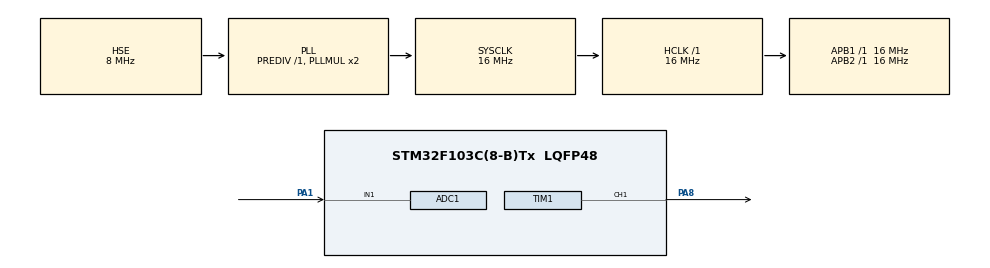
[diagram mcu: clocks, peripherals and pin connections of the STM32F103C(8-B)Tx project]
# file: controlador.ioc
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ADC1.Channel-0\#ChannelRegularConversion=ADC_CHANNEL_1
ADC1.NbrOfConversionFlag=1
ADC1.Rank-0\#ChannelRegularConversion=1
ADC1.SamplingTime-0\#ChannelRegularConversion=ADC_SAMPLETIME_1CYCLE_5
ADC1.master=1
Mcu.Family=STM32F1
Mcu.Name=STM32F103C(8-B)Tx
Mcu.Package=LQFP48
NVIC.PriorityGroup=NVIC_PRIORITYGROUP_4
NVIC.TIM2_IRQn=true\:0\:0\:false\:false\:true\:true\:true\:true
PA1.Signal=ADCx_IN1
PA13.Mode=Serial_Wire
PA13.Signal=SYS_JTMS-SWDIO
PA14.Mode=Serial_Wire
PA14.Signal=SYS_JTCK-SWCLK
PA8.Signal=S_TIM1_CH1
PD0-OSC_IN.Mode=HSE-External-Oscillator
PD0-OSC_IN.Signal=RCC_OSC_IN
PD1-OSC_OUT.Mode=HSE-External-Oscillator
PD1-OSC_OUT.Signal=RCC_OSC_OUT
ProjectManager.HeapSize=0x200
ProjectManager.StackSize=0x400
ProjectManager.TargetToolchain=STM32CubeIDE
RCC.AHBFreq_Value=16000000
RCC.APB1Freq_Value=16000000
RCC.APB1TimFreq_Value=16000000
RCC.APB2Freq_Value=16000000
RCC.APB2TimFreq_Value=16000000
RCC.HCLKFreq_Value=16000000
RCC.PLLSourceVirtual=RCC_PLLSOURCE_HSE
RCC.SYSCLKFreq_VALUE=16000000
RCC.SYSCLKSource=RCC_SYSCLKSOURCE_PLLCLK
RCC.USBFreq_Value=16000000
SH.ADCx_IN1.0=ADC1_IN1,IN1
SH.S_TIM1_CH1.0=TIM1_CH1,PWM Generation1 CH1
TIM1.Channel-PWM\ Generation1\ CH1=TIM_CHANNEL_1
TIM1.Period=3200-1
TIM2.Period=3200-1
TIM2.Prescaler=0
VP_TIM1_VS_ClockSourceINT.Mode=Internal
VP_TIM2_VS_ClockSourceINT.Mode=Internal
board=custom

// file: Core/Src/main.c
/* USER CODE BEGIN Header */
/**
  (1/16MHz) * 3200 = 200us -> 5000 Hz
  */
/* USER CODE END Header */
#include "main.h"

/* USER CODE BEGIN Includes */
#define TIMER_COUNTER (3200-1-500)
#define ARRAY_MAX_SIZE 2

// transdutor
#define ADC_SCALE_FACTOR (3.3f / 4096.0f)  //  3.3V em um ADC de 12bits
// #define TRANSDUCTOR_GAIN 0.1
#define TRANSDUCTOR_GAIN 0.085227273

// ref
#define PI 		3.14159265359f
#define F  		50     // Frequência da senoide (50 Hz)
#define Fs 		5000   // Frequência de amostragem (5 kHz)
#define Ts      (1.0f/Fs)
#define A  		6      // Amplitude
//#define OFFSET 	12
#define OFFSET 	10 // -2 por conta do teste empirco
#define WAVE_TABLE_SIZE (Fs/F)

// controlador
//opção 1
//#define Kp 0.062f
//#define Ki 0.17f
//#define Kd 0.05f
//opção 2
//#define Kp 0.07f
//#define Ki 0.18f
//#define Kd 0.05f
//opção 2
//#define Kp 0.07f
//#define Ki 0.2f
//#define Kd 0.05f
//opção 2
#define Kp 0.09f
#define Ki 0.2f
#define Kd 0.05f

// alimentação
// #define E 24.0f
#define E 30.0f

// duty_cycle
// 16MHz/5kHz = 3200
#define DUTY_CICLE_CONST (TIMER_COUNTER/E) // (SAMPLES_PER_PERIOD/E)

/* USER CODE END Includes */

ADC_HandleTypeDef hadc1;

TIM_HandleTypeDef htim1;
TIM_HandleTypeDef htim2;

void SystemClock_Config(void);
static void MX_GPIO_Init(void);
static void MX_ADC1_Init(void);
static void MX_TIM2_Init(void);
static void MX_TIM1_Init(void);

/* USER CODE BEGIN 0 */
int curr_idx = 0;

/*
 * Sinal de referencia sera uma senoidal com offset de 12V, amplitude de 6V e freq de 50 Hz
 *
 * Obs: ao invés de calcular a cada iteração eu poderia simplesmente armazernar todo um
 * periodo da senoidal já q o sinal de ref não se altera
 */
float ref_signal[WAVE_TABLE_SIZE] = {0};
uint8_t ref_idx = 0;

/*
 * Transdutor -> um dispositivo que transforma um tipo de energia em outro
 *
 * basicamente um sensor, o que em nosso caso seria o divisor de tensão que permite
 * lermos a tensão do sistema pelo ADC
 * */
float transductor_input[ARRAY_MAX_SIZE] = {0};
float prev_transductor_val = 0;
uint16_t adc_val = 0;

/*
 * Error é o array que contem o erro do sistema
 * basicamente é o valor da diferença entre o sinal de referencia e o sinal medido
 */
float error[ARRAY_MAX_SIZE] = {0};
float prev_error = 0;

/*
 * Controlador PID
 * uP(k) = Kp*e(k)
 * uI(k) = uI(k-1) + Ki*e(k)*Ts
 * uD(k) = Kd*((e(k) - e(k-1))/Ts)
 * uPID = uP(k) + uI(k) + uD(k)
 */
float cP = 0;
float cI[ARRAY_MAX_SIZE] = {0};
float cD = 0;
float prev_cI_output = 0;
float pid_output = 0;

/*
 * Duty cycle
 */
uint16_t duty_cycle = 0;

/* USER CODE END 0 */

int main(void)
{

  /* USER CODE BEGIN 1 */
  for (int i = 0; i < WAVE_TABLE_SIZE; i++) {
	ref_signal[i] = A * sinf(2 * PI * F * i * Ts) + OFFSET;
  }
  /* USER CODE END 1 */

  /* MCU Configuration--------------------------------------------------------*/

  /* Reset of all peripherals, Initializes the Flash interface and the Systick. */
  HAL_Init();

  /* Configure the system clock */
  SystemClock_Config();

  /* Initialize all configured peripherals */
  MX_GPIO_Init();
  MX_ADC1_Init();
  MX_TIM2_Init();
  MX_TIM1_Init();
  /* USER CODE BEGIN 2 */

  HAL_TIM_Base_Start_IT(&htim2);
  HAL_TIM_PWM_Start(&htim1, TIM_CHANNEL_1);
  __HAL_TIM_SET_COMPARE(&htim1, TIM_CHANNEL_1, TIMER_COUNTER/2);
  /* USER CODE END 2 */

  /* Infinite loop */
  while (1)
  {

  }
}

void SystemClock_Config(void)
{
  RCC_OscInitTypeDef RCC_OscInitStruct = {0};
  RCC_ClkInitTypeDef RCC_ClkInitStruct = {0};
  RCC_PeriphCLKInitTypeDef PeriphClkInit = {0};

  /** Initializes the RCC Oscillators according to the specified parameters
  * in the RCC_OscInitTypeDef structure.
  */
  RCC_OscInitStruct.OscillatorType = RCC_OSCILLATORTYPE_HSE;
  RCC_OscInitStruct.HSEState = RCC_HSE_ON;
  RCC_OscInitStruct.HSEPredivValue = RCC_HSE_PREDIV_DIV1;
  RCC_OscInitStruct.HSIState = RCC_HSI_ON;
  RCC_OscInitStruct.PLL.PLLState = RCC_PLL_ON;
  RCC_OscInitStruct.PLL.PLLSource = RCC_PLLSOURCE_HSE;
  RCC_OscInitStruct.PLL.PLLMUL = RCC_PLL_MUL2;
  if (HAL_RCC_OscConfig(&RCC_OscInitStruct) != HAL_OK)
  {
    Error_Handler();
  }

  /** Initializes the CPU, AHB and APB buses clocks
  */
  RCC_ClkInitStruct.ClockType = RCC_CLOCKTYPE_HCLK|RCC_CLOCKTYPE_SYSCLK
                              |RCC_CLOCKTYPE_PCLK1|RCC_CLOCKTYPE_PCLK2;
  RCC_ClkInitStruct.SYSCLKSource = RCC_SYSCLKSOURCE_PLLCLK;
  RCC_ClkInitStruct.AHBCLKDivider = RCC_SYSCLK_DIV1;
  RCC_ClkInitStruct.APB1CLKDivider = RCC_HCLK_DIV1;
  RCC_ClkInitStruct.APB2CLKDivider = RCC_HCLK_DIV1;

  if (HAL_RCC_ClockConfig(&RCC_ClkInitStruct, FLASH_LATENCY_0) != HAL_OK)
  {
    Error_Handler();
  }
  PeriphClkInit.PeriphClockSelection = RCC_PERIPHCLK_ADC;
  PeriphClkInit.AdcClockSelection = RCC_ADCPCLK2_DIV2;
  if (HAL_RCCEx_PeriphCLKConfig(&PeriphClkInit) != HAL_OK)
  {
    Error_Handler();
  }
}

static void MX_ADC1_Init(void)
{

  ADC_ChannelConfTypeDef sConfig = {0};

  /** Common config
  */
  hadc1.Instance = ADC1;
  hadc1.Init.ScanConvMode = ADC_SCAN_DISABLE;
  hadc1.Init.ContinuousConvMode = DISABLE;
  hadc1.Init.DiscontinuousConvMode = DISABLE;
  hadc1.Init.ExternalTrigConv = ADC_SOFTWARE_START;
  hadc1.Init.DataAlign = ADC_DATAALIGN_RIGHT;
  hadc1.Init.NbrOfConversion = 1;
  if (HAL_ADC_Init(&hadc1) != HAL_OK)
  {
    Error_Handler();
  }

  /** Configure Regular Channel
  */
  sConfig.Channel = ADC_CHANNEL_1;
  sConfig.Rank = ADC_REGULAR_RANK_1;
  sConfig.SamplingTime = ADC_SAMPLETIME_1CYCLE_5;
  if (HAL_ADC_ConfigChannel(&hadc1, &sConfig) != HAL_OK)
  {
    Error_Handler();
  }

}

static void MX_TIM1_Init(void)
{

  TIM_ClockConfigTypeDef sClockSourceConfig = {0};
  TIM_MasterConfigTypeDef sMasterConfig = {0};
  TIM_OC_InitTypeDef sConfigOC = {0};
  TIM_BreakDeadTimeConfigTypeDef sBreakDeadTimeConfig = {0};

  htim1.Instance = TIM1;
  htim1.Init.Prescaler = 0;
  htim1.Init.CounterMode = TIM_COUNTERMODE_UP;
  htim1.Init.Period = 3200-1;
  htim1.Init.ClockDivision = TIM_CLOCKDIVISION_DIV1;
  htim1.Init.RepetitionCounter = 0;
  htim1.Init.AutoReloadPreload = TIM_AUTORELOAD_PRELOAD_DISABLE;
  if (HAL_TIM_Base_Init(&htim1) != HAL_OK)
  {
    Error_Handler();
  }
  sClockSourceConfig.ClockSource = TIM_CLOCKSOURCE_INTERNAL;
  if (HAL_TIM_ConfigClockSource(&htim1, &sClockSourceConfig) != HAL_OK)
  {
    Error_Handler();
  }
  if (HAL_TIM_PWM_Init(&htim1) != HAL_OK)
  {
    Error_Handler();
  }
  sMasterConfig.MasterOutputTrigger = TIM_TRGO_RESET;
  sMasterConfig.MasterSlaveMode = TIM_MASTERSLAVEMODE_DISABLE;
  if (HAL_TIMEx_MasterConfigSynchronization(&htim1, &sMasterConfig) != HAL_OK)
  {
    Error_Handler();
  }
  sConfigOC.OCMode = TIM_OCMODE_PWM1;
  sConfigOC.Pulse = 0;
  sConfigOC.OCPolarity = TIM_OCPOLARITY_HIGH;
  sConfigOC.OCNPolarity = TIM_OCNPOLARITY_HIGH;
  sConfigOC.OCFastMode = TIM_OCFAST_DISABLE;
  sConfigOC.OCIdleState = TIM_OCIDLESTATE_RESET;
  sConfigOC.OCNIdleState = TIM_OCNIDLESTATE_RESET;
  if (HAL_TIM_PWM_ConfigChannel(&htim1, &sConfigOC, TIM_CHANNEL_1) != HAL_OK)
  {
    Error_Handler();
  }
  sBreakDeadTimeConfig.OffStateRunMode = TIM_OSSR_DISABLE;
  sBreakDeadTimeConfig.OffStateIDLEMode = TIM_OSSI_DISABLE;
  sBreakDeadTimeConfig.LockLevel = TIM_LOCKLEVEL_OFF;
  sBreakDeadTimeConfig.DeadTime = 0;
  sBreakDeadTimeConfig.BreakState = TIM_BREAK_DISABLE;
  sBreakDeadTimeConfig.BreakPolarity = TIM_BREAKPOLARITY_HIGH;
  sBreakDeadTimeConfig.AutomaticOutput = TIM_AUTOMATICOUTPUT_DISABLE;
  if (HAL_TIMEx_ConfigBreakDeadTime(&htim1, &sBreakDeadTimeConfig) != HAL_OK)
  {
    Error_Handler();
  }
  HAL_TIM_MspPostInit(&htim1);

}

static void MX_TIM2_Init(void)
{

  TIM_ClockConfigTypeDef sClockSourceConfig = {0};
  TIM_MasterConfigTypeDef sMasterConfig = {0};

  htim2.Instance = TIM2;
  htim2.Init.Prescaler = 0;
  htim2.Init.CounterMode = TIM_COUNTERMODE_UP;
  htim2.Init.Period = 3200-1;
  htim2.Init.ClockDivision = TIM_CLOCKDIVISION_DIV1;
  htim2.Init.AutoReloadPreload = TIM_AUTORELOAD_PRELOAD_DISABLE;
  if (HAL_TIM_Base_Init(&htim2) != HAL_OK)
  {
    Error_Handler();
  }
  sClockSourceConfig.ClockSource = TIM_CLOCKSOURCE_INTERNAL;
  if (HAL_TIM_ConfigClockSource(&htim2, &sClockSourceConfig) != HAL_OK)
  {
    Error_Handler();
  }
  sMasterConfig.MasterOutputTrigger = TIM_TRGO_RESET;
  sMasterConfig.MasterSlaveMode = TIM_MASTERSLAVEMODE_DISABLE;
  if (HAL_TIMEx_MasterConfigSynchronization(&htim2, &sMasterConfig) != HAL_OK)
  {
    Error_Handler();
  }

}

static void MX_GPIO_Init(void)
{

  /* GPIO Ports Clock Enable */
  __HAL_RCC_GPIOD_CLK_ENABLE();
  __HAL_RCC_GPIOA_CLK_ENABLE();

}

/* USER CODE BEGIN 4 */
void HAL_TIM_PeriodElapsedCallback(TIM_HandleTypeDef *htim)
{
	if(htim->Instance == TIM2)
	{
		prev_transductor_val = transductor_input[(curr_idx - 1 + ARRAY_MAX_SIZE) % ARRAY_MAX_SIZE];
		error[curr_idx] = ref_signal[ref_idx] - prev_transductor_val;

		// Inicia a conversão ADC
		HAL_ADC_Start(&hadc1);

		// Espera a conversão estar pronta (timeout opcional)
		if(HAL_ADC_PollForConversion(&hadc1, 0) == HAL_OK)
		{
			adc_val = HAL_ADC_GetValue(&hadc1);
			transductor_input[curr_idx] = adc_val * ADC_SCALE_FACTOR / TRANSDUCTOR_GAIN;
			prev_cI_output = cI[(curr_idx - 1 + ARRAY_MAX_SIZE) % ARRAY_MAX_SIZE];
			prev_error = error[(curr_idx - 1 + ARRAY_MAX_SIZE) % ARRAY_MAX_SIZE];

			cP = Kp * error[curr_idx];
			cI[curr_idx] = prev_cI_output + Ki * error[curr_idx];
			cD = Kd * (error[curr_idx] - prev_error);
			pid_output = cP + cI[curr_idx] + cD;

			if(pid_output < 0){
				pid_output = 0;
			}
			else if(pid_output > E){
				pid_output = E;
			}

			duty_cycle = pid_output * DUTY_CICLE_CONST;
			__HAL_TIM_SET_COMPARE(&htim1, TIM_CHANNEL_1, duty_cycle); // mudar o duty_cycle

			curr_idx = (curr_idx + 1) % ARRAY_MAX_SIZE;
			ref_idx = (ref_idx + 1) % WAVE_TABLE_SIZE;
		}
		HAL_ADC_Stop(&hadc1);
	}
}

/* USER CODE END 4 */

void Error_Handler(void)
{
  __disable_irq();
  while (1)
  {
  }
}
